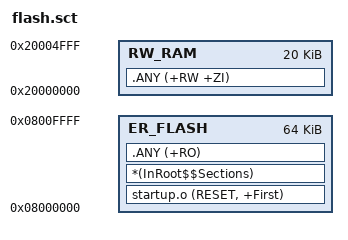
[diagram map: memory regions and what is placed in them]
LR_FLASH 0x08000000 0x00010000 {
    ER_FLASH 0x08000000 0x00010000 {
        startup.o (RESET, +First)
        *(InRoot$$Sections)
        .ANY (+RO)
    }
    RW_RAM 0x20000000 0x00005000 {
        .ANY (+RW +ZI)
    }
}
